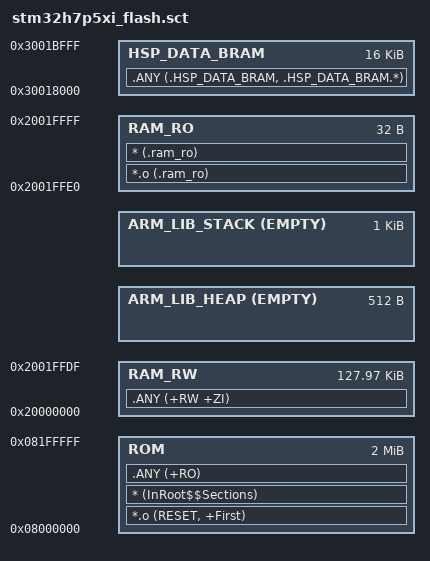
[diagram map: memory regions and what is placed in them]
#! armclang -E --target=arm-arm-none-eabi -mcpu=cortex-m7 -xc
; command above MUST be in first line (no comment above!)

; ******************************************************************************
; * @file    stm32h7p5xi_flash.sct
; * @brief   Linker File
; ******************************************************************************
; * @attention
; *
; * Copyright (c) 2026 STMicroelectronics.
; * All rights reserved.
; *
; * This software is licensed under terms that can be found in the LICENSE file
; * in the root directory of this software component.
; * If no LICENSE file comes with this software, it is provided AS-IS.
; *
; ******************************************************************************

#define __HEAP_SIZE 0x200
#define __STACK_SIZE 0x400


ROM 0x8000000 0x200000
{
  ROM 0x8000000 0x200000
  {
    *.o (RESET, +First)
    * (InRoot$$Sections)
    .ANY (+RO)
  }

  RAM_RW 0x20000000 0x1FFE0
  {
    .ANY (+RW +ZI)
  }

  ARM_LIB_HEAP AlignExpr(+0, 8) EMPTY  __HEAP_SIZE
  {
  }

  ARM_LIB_STACK AlignExpr(+0, 8) EMPTY  __STACK_SIZE
  {
  }

  RAM_RO 0x2001FFE0 0x20
  {
    *.o (.ram_ro)
    * (.ram_ro)
  }
}

HSP_DATA_BRAM 0x30018000 0x4000
{
  HSP_DATA_BRAM 0x30018000 0x4000
  {
    .ANY (.HSP_DATA_BRAM, .HSP_DATA_BRAM.*)
  }
}
